# NUC400_v1 register map
File version: 1.0
Registers are 32-bit, read-write, reset 0x0 unless marked. A register's access mark holds for its fields unless they carry their own. Offsets are from the block's base; [hi:lo] are bit positions; {n}, {i} and the like mark numbered series.

## I2S — I2S Register Map
Base 0x40048000
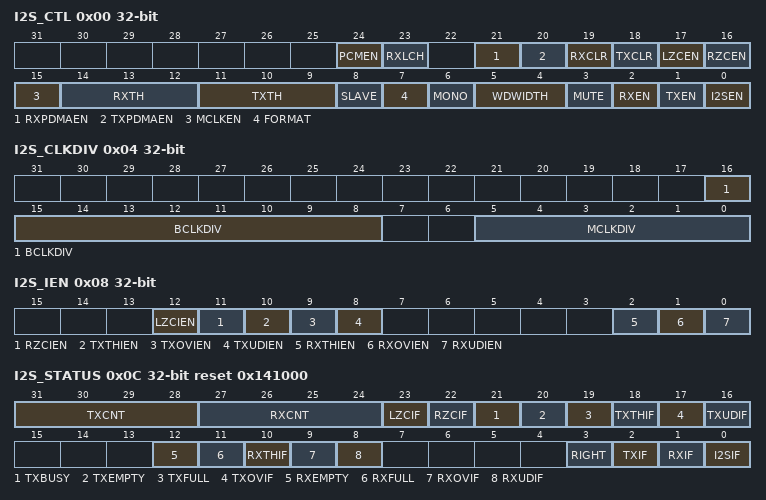
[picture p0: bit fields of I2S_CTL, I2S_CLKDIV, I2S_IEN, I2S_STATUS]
0x00 I2S_CTL — I2S Control Register
  [24] PCMEN — PCM Interface Enable Bit
    0=I2S Interface; 1=PCM Interface
  [23] RXLCH — Receive Left Channel Enable Bit
    0=Receives right channel data when monaural format is selected; 1=Receives left channel data when monaural format is selected
  [21] RXPDMAEN — Receive DMA Enable Bit. Note: When RX DMA is enabled, I2S requests DMA to transfer data from receive FIFO to SRAM if FIFO is not empty.
    0=RX DMA Disabled; 1=RX DMA Enabled
  [20] TXPDMAEN — Transmit DMA Enable Bit. Note: When TX DMA is enables, I2S request DMA to transfer data from SRAM to transmit FIFO if FIFO is not full.
    0=TX DMA Disabled; 1=TX DMA Enabled
  [19] RXCLR — Clear Receive FIFO. Note1: Write 1 to clear receive FIFO, internal pointer is reset to FIFO start point, and RXCNT (I2S_STATUS[27:24]) returns 0 and receive FIFO becomes empty. Note2: This bit is cleared by hardware automatically, read it return zero.
    0=No Effect; 1=Clear RX FIFO
  [18] TXCLR — Clear Transmit FIFO. Note1: Write 1 to clear transmit FIFO, internal pointer is reset to FIFO start point, and TXCNT(I2S_STATUS[31:28]) returns 0 and transmit FIFO becomes empty but data in transmit FIFO is not changed. Note2: This bit is clear by hardware automatically, read it return zero.
    0=No Effect; 1=Clear TX FIFO
  [17] LZCEN — Left Channel Zero-Cross Detect Enable Bit. Note1: If this bit is set to 1, when left channel data sign bit change or next shift data bits are all zero then LZCIF(I2S_STATUS[23]) flag is set to 1. Note2: If LZCIF Flag is set to 1, the left channel will be mute.
    0=Left channel zero-cross detect Disabled; 1=Left channel zero-cross detect Enabled
  [16] RZCEN — Right Channel Zero-Cross Detection Enable Bit. Note1: If this bit is set to 1, when right channel data sign bit change or next shift data bits are all zero then RZCIF(I2S_STATUS[22]) flag is set to 1. Note2: If RZCIF Flag is set to 1, the right channel will be mute.
    0=Right channel zero-cross detect Disabled; 1=Right channel zero-cross detect Enabled
  [15] MCLKEN — Master Clock Enable Bit. Note: If the external crystal clock in NuMicro( NUC442/NUC472 series is frequency 2*N*256fs, software can program MCLKDIV(I2S_CLKDIV[5:0]) to get 256fs clock to audio codec chip.
    0=Master clock Disabled; 1=Master clock Enabled
  [14:12] RXTH — Receive FIFO Threshold Level. Note: When received data word(s) in buffer is equal to or higher than threshold level then RXTHIF flag is set.
    {v}={v+1} word data in receive FIFO (v=0..7)
  [11:9] TXTH — Transmit FIFO Threshold Level. Note: If remain data word(s) in transmit FIFO is the same or less than threshold level then TXTHIF flag is set.
    0=0 word data in transmit FIFO; 1=1 word data in transmit FIFO; {v}={v} words data in transmit FIFO (v=2..7)
  [8] SLAVE — Slave Mode Enable Bit. Note: I2S can operate as master or slave. For Master mode, I2S_BCLK and I2S_LRCLK pins are output mode and send bit clock from NuMicro( NUC442/NUC472 series to Audio CODEC chip. In Slave mode, I2S_BCLK and I2S_LRCLK pins are input mode and I2S_BCLK and I2S_LRCLK signals are received from outer Audio CODEC chip.
    0=Master mode; 1=Slave mode
  [7] FORMAT — Data Format Selection
    0=I2S data format. PCM mode A; 1=MSB justified data format. PCM mode B
  [6] MONO — Monaural Data Control. Note: when chip records data, only right channel data will be saved if monaural format is select.
    0=Data is stereo format; 1=Data is monaural format
  [5:4] WDWIDTH — Word Width
    0=data is 8-bit; 1=data is 16-bit; 2=data is 24-bit; 3=data is 32-bit
  [3] MUTE — Transmit Mute Enable Bit
    0=Transmit data is shifted from buffer; 1=Transmit zero data
  [2] RXEN — Receive Enable Bit
    0=Data receiving Disabled; 1=Data receiving Enabled
  [1] TXEN — Transmit Enable Bit
    0=Data transmission Disabled; 1=Data transmission Enabled
  [0] I2SEN — I2S Controller Enable Bit
    0=Disabled; 1=Enabled
0x04 I2S_CLKDIV — I2S Clock Divider Register
  [16:8] BCLKDIV — Bit Clock Divider. If I2S operates in Master mode, bit clock is provided by the NuMicro( NUC442/NUC472 series. Software can program these bits to generate sampling rate clock frequency. Note: F_BCLK is the frequency of BCLK and F_I2SCLK is the frequency of I2S_CLK
  [5:0] MCLKDIV — Master Clock Divider. If chip external crystal frequency is (2xMCLKDIV)*256fs then software can program these bits to generate 256fs clock frequency to audio codec chip. If MCLKDIV is set to 0, MCLK is the same as external clock input. Note: F_MCLK is the frequency of MCLK, and F_i2SCLK is the frequency of the I2S_CLK
0x08 I2S_IEN — I2S Interrupt Enable Register
  [all] fields
    0=Interrupt Disabled; 1=Interrupt Enabled
  [12] LZCIEN — Left Channel Zero-Cross Interrupt Enable Bit. Note: Interrupt occurs if this bit is set to 1 and left channel zero-cross
  [11] RZCIEN — Right Channel Zero-Cross Interrupt Enable Bit. Note: Interrupt occurs if this bit is set to 1 and right channel zero-cross
  [10] TXTHIEN — Transmit FIFO Threshold Level Interrupt Enable Bit. Note: Interrupt occurs if this bit is set to 1 and data words in transmit FIFO is less than TXTH(I2S_CTL[11:9]).
  [9] TXOVIEN — Transmit FIFO Overflow Interrupt Enable Bit. Note: Interrupt occurs if this bit is set to 1 and TXOVIF(I2S_STATUS[17]) flag is set to 1
  [8] TXUDIEN — Transmit FIFO Underflow Interrupt Enable Bit. Note: Interrupt occur if this bit is set to 1 and TXUDIF(I2S_STATUS[16]) flag is set to 1.
  [2] RXTHIEN — Receive FIFO Threshold Level Interrupt Enable Bit. Note: When data word in receive FIFO is equal or higher than RXTH(I2S_CTL[14:12]) and the RXTHIF bit is set to 1. If RXTHIEN bit is enabled, interrupt occur.
  [1] RXOVIEN — Receive FIFO Overflow Interrupt Enable Bit. Note: Interrupt occurs if this bit is set to 1 and RXOVIF(I2S_STATUS[9]) flag is set to 1
  [0] RXUDIEN — Receive FIFO Underflow Interrupt E Enable Bit. Note: If software reads receive FIFO when it is empty then RXUDIF(I2S_STATUS[8]) flag is set to 1.
0x0C I2S_STATUS reset 0x141000
  [31:28] TXCNT ro — Transmit FIFO Level (Read Only). These bits indicate word number in transmit FIFO
    0=No data; 1=1 word in transmit FIFO; 8=8 words in transmit FIFO
  [27:24] RXCNT ro — Receive FIFO Level (Read Only). These bits indicate word number in receive FIFO
    0=No data; 1=1 word in receive FIFO; 8=8 words in receive FIFO
  [23] LZCIF — Left Channel Zero-Cross Flag. It indicates left channel next sample data sign bit is changed or all data bits are zero. Note: Write 1 to clear this bit to 0.
    0=No zero-cross; 1=Left channel zero-cross is detected
  [22] RZCIF — Right Channel Zero-Cross Flag. It indicates right channel next sample data sign bit is changed or all data bits are zero. Note: Write 1 to clear this bit to 0.
    0=No zero-cross; 1=Right channel zero-cross is detected
  [21] TXBUSY ro — Transmit Busy (Read Only). Note: This bit is cleared to 0 when all data in transmit FIFO and shift buffer is shifted out. And set to 1 when 1st data is load to shift buffer.
    0=Transmit shift buffer is empty; 1=Transmit shift buffer is busy
  [20] TXEMPTY ro — Transmit FIFO Empty (Read Only). This bit reflect data word number in transmit FIFO is zero
    0=Not empty; 1=Empty
  [19] TXFULL ro — Transmit FIFO Full (Read Only). This bit reflect data word number in transmit FIFO is 8
    0=Not full; 1=Full
  [18] TXTHIF ro — Transmit FIFO Threshold Flag (Read Only). Note: When data word(s) in transmit FIFO is equal or lower than threshold value set in TXTH(I2S_CTL[11:9]) the TXTHIF bit becomes to 1. It keeps at 1 till TXCNT is higher than TXTH after software write TXFIFO register.
    0=Data word(s) in FIFO is higher than threshold level; 1=Data word(s) in FIFO is equal or lower than threshold level
  [17] TXOVIF — Transmit FIFO Overflow Flag. Note1: Write data to transmit FIFO when it is full and this bit set to 1. Note2: Write 1 to clear this bit to 0.
    0=No overflow; 1=Overflow
  [16] TXUDIF — Transmit FIFO Underflow Flag. Note1: When transmit FIFO is empty and shift logic hardware read data from data FIFO causes this set to 1. Note2: Write 1 to clear this bit to 0.
    0=No underflow; 1=Underflow
  [12] RXEMPTY ro — Receive FIFO Empty (Read Only). Note: This bit reflects data words number in receive FIFO is zero
    0=Not empty; 1=Empty
  [11] RXFULL ro — Receive FIFO Full (Read Only). Note: This bit reflects data words number in receive FIFO is 8.
    0=Not full; 1=Full
  [10] RXTHIF ro — Receive FIFO Threshold Flag (Read Only). Note: When data word(s) in receive FIFO is equal or higher than threshold value set in RXTH(I2S_CTL[14:12]) the RXTHIF bit becomes to 1. It keeps at 1 till RXCNT less than RXTH after software read RXFIFO register.
    0=Data word(s) in FIFO is lower than threshold level; 1=Data word(s) in FIFO is equal or higher than threshold level
  [9] RXOVIF — Receive FIFO Overflow Flag. Note1: When receive FIFO is full and receive hardware attempt write to data into receive FIFO then this bit is set to 1, data in 1st buffer is overwrote. Note2: Write 1 to clear this bit to 0.
    0=No overflow occur; 1=Overflow occur
  [8] RXUDIF — Receive FIFO Underflow Flag. Note1: When receive FIFO is empty, and software reads the receive FIFO again. This bit will be set to 1, and it indicates underflow situation occurs. Note2: Write 1 to clear this bit to zero
    0=No underflow occur; 1=Underflow occur
  [3] RIGHT ro — Right Channel (Read Only). Note: This bit indicate current transmit data is belong to right channel
    0=Left channel; 1=Right channel
  [2] TXIF ro — I2S Transmit Interrupt (Read Only)
    0=No transmit interrupt; 1=Transmit interrupt
  [1] RXIF ro — I2S Receive Interrupt (Read Only)
    0=No receive interrupt; 1=Receive interrupt
  [0] I2SIF ro — I2S Interrupt Flag (Read Only). Note: It is wire-OR of TXIF and RXIF bits.
    0=No I2S interrupt; 1=I2S interrupt
0x10 I2S_TX wo — I2S Transmit FIFO Register
  [31:0] TX — Transmit FIFO Bits. I2S contains 8 words (8x32 bit) data buffer for data transmit. Write data to this register to prepare data for transmit. The remaining word number is indicated by TXCNT(I2S_STATUS[31:28]).
0x14 I2S_RX ro — I2S Receive FIFO Register
  [31:0] RX — Receive FIFO Bits. I2S contains 8 words (8x32 bit) data buffer for data receive. Read this register to get data in FIFO. The remaining data word number is indicated by RXCNT(I2S_STATUS[27:24]).
